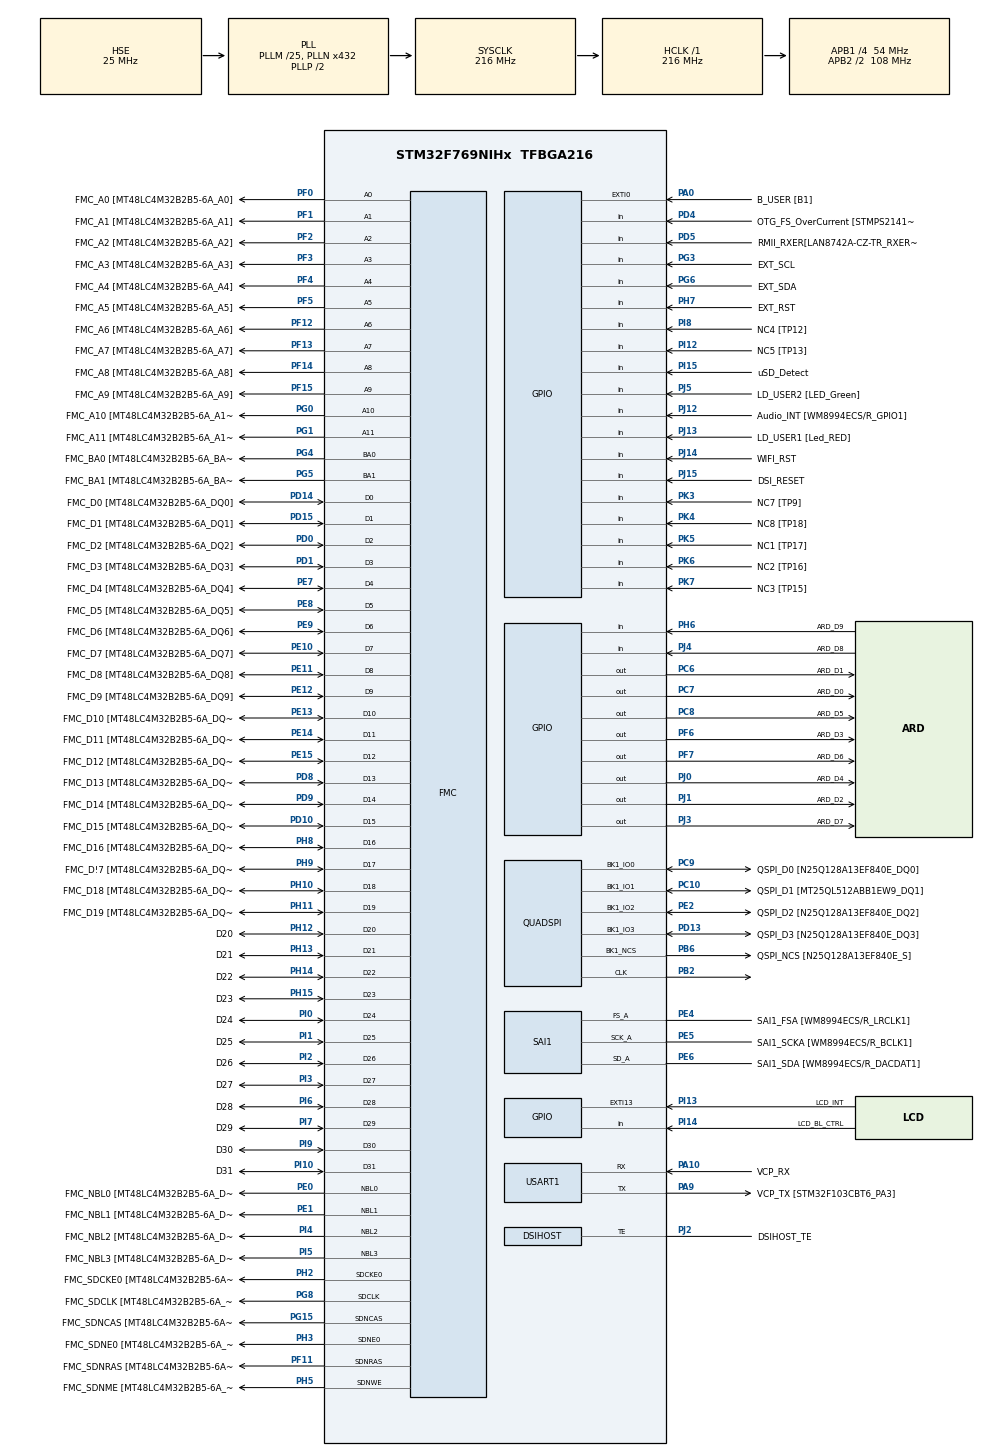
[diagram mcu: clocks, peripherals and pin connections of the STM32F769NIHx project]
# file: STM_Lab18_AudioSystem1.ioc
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CORTEX_M7.CPU_DCache=Enabled
CORTEX_M7.CPU_ICache=Enabled
DSIHOST.CommandSize=400
DSIHOST_CKN.GPIO_Label=DSI_CK_N
DSIHOST_CKN.Mode=DSIHost_Adapted_TE
DSIHOST_CKN.Signal=DSIHOST_CKN
DSIHOST_CKP.GPIO_Label=DSI_CK_P
DSIHOST_CKP.Mode=DSIHost_Adapted_TE
DSIHOST_CKP.Signal=DSIHOST_CKP
DSIHOST_D0N.GPIO_Label=DSI_D0_N
DSIHOST_D0N.Mode=DSIHost_Adapted_TE
DSIHOST_D0N.Signal=DSIHOST_D0N
DSIHOST_D0P.GPIO_Label=DSI_D0_p
DSIHOST_D0P.Mode=DSIHost_Adapted_TE
DSIHOST_D0P.Signal=DSIHOST_D0P
DSIHOST_D1N.GPIO_Label=DSI_D1_N
DSIHOST_D1N.Mode=DSIHost_Adapted_TE
DSIHOST_D1N.Signal=DSIHOST_D1N
DSIHOST_D1P.GPIO_Label=DSI_D1_P
DSIHOST_D1P.Mode=DSIHost_Adapted_TE
DSIHOST_D1P.Signal=DSIHOST_D1P
FMC.CASLatency1=FMC_SDRAM_CAS_LATENCY_3
FREERTOS.Queues01=audioQueue,16,uint8_t,0,Dynamic,NULL,NULL
FREERTOS.Tasks01=audioTask,2,128,StartAudioTask,Default,NULL,Dynamic,NULL,NULL;auxTask,-3,128,auxTaskStart,Default,NULL,Dynamic,NULL,NULL;myFlashAliveTas,-3,128,StartFlashAliveTask,Default,NULL,Dynamic,NULL,NULL
FREERTOS.configUSE_NEWLIB_REENTRANT=1
LTDC.ActiveW=800
LTDC.HBP=1
LTDC.HFP=1
LTDC.HSync=1
LTDC.VBP=1
LTDC.VFP=1
LTDC.VSync=1
Mcu.Family=STM32F7
Mcu.Name=STM32F769NIHx
Mcu.Package=TFBGA216
NVIC.DMA2D_IRQn=true\:5\:0\:false\:false\:true\:true\:true\:true\:true
NVIC.DSI_IRQn=true\:5\:0\:true\:false\:true\:true\:true\:true\:true
NVIC.LTDC_IRQn=true\:5\:0\:false\:false\:true\:true\:true\:true\:true
NVIC.PriorityGroup=NVIC_PRIORITYGROUP_4
NVIC.RCC_IRQn=true\:5\:0\:false\:false\:true\:true\:true\:false\:true
NVIC.TIM6_DAC_IRQn=true\:15\:0\:false\:false\:true\:false\:false\:true\:true
NVIC.TimeBase=TIM6_DAC_IRQn
NVIC.TimeBaseIP=TIM6
PA0/WKUP.GPIO_Label=B_USER [B1]
PA0/WKUP.Signal=GPXTI0
PA1.GPIO_Label=RMII_REF_CLK [LAN8742A-CZ-TR_REFCLK0]
PA1.Signal=ETH_REF_CLK
PA10.GPIO_Label=VCP_RX 
PA10.Mode=Asynchronous
PA10.Signal=USART1_RX
PA11.GPIO_Label=SPI2_NSS
PA11.Signal=SPI2_NSS
PA12.GPIO_Label=ARD_D13/SCK
PA12.GPIO_Mode=GPIO_MODE_AF_PP
PA12.GPIO_PuPd=GPIO_NOPULL
PA12.GPIO_Speed=GPIO_SPEED_FREQ_LOW
PA12.Signal=SPI2_SCK
PA13.GPIO_Label=SWDIO
PA13.Mode=Serial_Wire
PA13.Signal=SYS_JTMS-SWDIO
PA14.GPIO_Label=SWCLK
PA14.Mode=Serial_Wire
PA14.Signal=SYS_JTCK-SWCLK
PA15.GPIO_Label=CEC
PA15.Signal=CEC
PA2.GPIO_Label=RMII_MDIO [LAN8742A-CZ-TR_MDIO]
PA2.Signal=ETH_MDIO
PA3.GPIO_Label=ULPI_D0 [USB3320C-EZK_D0]
PA3.Signal=USB_OTG_HS_ULPI_D0
PA4.GPIO_Label=ARD_A1
PA4.Signal=ADCx_IN4
PA5.GPIO_Label=ULPI_CLK [USB3320C-EZK_CLKOUT]
PA5.Signal=USB_OTG_HS_ULPI_CK
PA6.GPIO_Label=ARD_A0
PA6.Signal=ADCx_IN6
PA7.GPIO_Label=RMII_CRS_DV [LAN8742A-CZ-TR_CRS_DV]
PA7.Signal=ETH_CRS_DV
PA8.GPIO_Label=CEC_CLK [TP2]
PA8.Signal=RCC_MCO_1
PA9.GPIO_Label=VCP_TX [STM32F103CBT6_PA3]
PA9.GPIO_Mode=GPIO_MODE_AF_PP
PA9.GPIO_PuPd=GPIO_NOPULL
PA9.GPIO_Speed=GPIO_SPEED_FREQ_LOW
PA9.Mode=Asynchronous
PA9.Signal=USART1_TX
PB0.GPIO_Label=ULPI_D1 [USB3320C-EZK_D1]
PB0.Signal=USB_OTG_HS_ULPI_D1
PB1.GPIO_Label=ULPI_D2 [USB3320C-EZK_D2]
PB1.Signal=USB_OTG_HS_ULPI_D2
PB10.GPIO_Label=ULPI_D3 [USB3320C-EZK_D3]
PB10.Signal=USB_OTG_HS_ULPI_D3
PB11.GPIO_Label=ULPI_D4 [USB3320C-EZK_D4]
PB11.Signal=USB_OTG_HS_ULPI_D4
PB12.GPIO_Label=ULPI_D5 [USB3320C-EZK_D5]
PB12.Signal=USB_OTG_HS_ULPI_D5
PB13.GPIO_Label=ULPI_D6 [USB3320C-EZK_D6]
PB13.Signal=USB_OTG_HS_ULPI_D6
PB14.GPIO_Label=ARDUINO MISO/D12
PB14.GPIO_Mode=GPIO_MODE_AF_PP
PB14.GPIO_PuPd=GPIO_NOPULL
PB14.GPIO_Speed=GPIO_SPEED_FREQ_LOW
PB14.Signal=SPI2_MISO
PB15.GPIO_Label=ARDUINO MOSI/PWM/D11
PB15.GPIO_Mode=GPIO_MODE_AF_PP
PB15.GPIO_PuPd=GPIO_NOPULL
PB15.GPIO_Speed=GPIO_SPEED_FREQ_LOW
PB15.Signal=SPI2_MOSI
PB2.Mode=Single Bank 1
PB2.Signal=QUADSPI_CLK
PB3.GPIO_Label=uSD_D2
PB3.Signal=SDMMC2_D2
PB4.GPIO_Label=uSD_D3
PB4.Signal=SDMMC2_D3
PB5.GPIO_Label=ULPI_D7 [USB3320C-EZK_D7]
PB5.Signal=USB_OTG_HS_ULPI_D7
PB6.GPIO_Label=QSPI_NCS [N25Q128A13EF840E_S]
PB6.Mode=Single Bank 1
PB6.Signal=QUADSPI_BK1_NCS
PB7.GPIO_Label=AUDIO_SDA [WM8994ECS/R_SDA]
PB7.Signal=I2C4_SDA
PB8.GPIO_Label=ARDUINO SCL/D15
PB8.GPIO_Mode=GPIO_MODE_AF_OD
PB8.GPIO_PuPd=GPIO_NOPULL
PB8.GPIO_Speed=GPIO_SPEED_FREQ_LOW
PB8.Signal=I2C1_SCL
PB9.GPIO_Label=ARDUINO SDA/D14
PB9.GPIO_Mode=GPIO_MODE_AF_OD
PB9.GPIO_PuPd=GPIO_NOPULL
PB9.GPIO_Speed=GPIO_SPEED_FREQ_LOW
PB9.Signal=I2C1_SDA
PC0.GPIO_Label=ULPI_STP [USB3320C-EZK_STP]
PC0.Signal=USB_OTG_HS_ULPI_STP
PC1.GPIO_Label=RMII_MDC [LAN8742A-CZ-TR_MDC]
PC1.Signal=ETH_MDC
PC10.GPIO_Label=QSPI_D1 [MT25QL512ABB1EW9_DQ1]
PC10.Mode=Single Bank 1
PC10.Signal=QUADSPI_BK1_IO1
PC11.GPIO_Label=DFSDM_DATIN5 [TP100]
PC11.Signal=S_DATAIN5DFSDM1
PC12.GPIO_Label=WIFI_RX
PC12.Signal=UART5_TX
PC14/OSC32_IN.GPIO_Label=RCC_OSC32_IN
PC14/OSC32_IN.Signal=RCC_OSC32_IN
PC15/OSC32_OUT.GPIO_Label=RCC_OSC32_OUT
PC15/OSC32_OUT.Signal=RCC_OSC32_OUT
PC2.GPIO_Label=ARD_A2
PC2.Signal=ADCx_IN12
PC3.GPIO_Label=DFSDM_DATIN1 [TP101]
PC3.Signal=S_DATAIN1DFSDM1
PC4.GPIO_Label=RMII_RXD0 [LAN8742A-CZ-TR_RXD0]
PC4.Signal=ETH_RXD0
PC5.GPIO_Label=RMII_RXD1 [LAN8742A-CZ-TR_RXD1]
PC5.Signal=ETH_RXD1
PC6.GPIO_Label=ARD_D1
PC6.Signal=GPIO_Output
PC7.GPIO_Label=ARD_D0
PC7.Signal=GPIO_Output
PC8.GPIO_Label=ARD_D5
PC8.Signal=GPIO_Output
PC9.GPIO_Label=QSPI_D0 [N25Q128A13EF840E_DQ0]
PC9.Mode=Single Bank 1
PC9.Signal=QUADSPI_BK1_IO0
PD0.GPIO_Label=FMC_D2 [MT48LC4M32B2B5-6A_DQ2]
PD0.Signal=FMC_D2_DA2
PD1.GPIO_Label=FMC_D3 [MT48LC4M32B2B5-6A_DQ3]
PD1.Signal=FMC_D3_DA3
PD10.GPIO_Label=FMC_D15 [MT48LC4M32B2B5-6A_DQ15]
PD10.Signal=FMC_D15_DA15
PD11.GPIO_Label=SPDIF_TX [TP20]
PD11.Signal=SAI2_SD_A
PD12.GPIO_Label=AUDIO_SCL [WM8994ECS/R_SCLK]
PD12.Signal=I2C4_SCL
PD13.GPIO_Label=QSPI_D3 [N25Q128A13EF840E_DQ3]
PD13.Mode=Single Bank 1
PD13.Signal=QUADSPI_BK1_IO3
PD14.GPIO_Label=FMC_D0 [MT48LC4M32B2B5-6A_DQ0]
PD14.Signal=FMC_D0_DA0
PD15.GPIO_Label=FMC_D1 [MT48LC4M32B2B5-6A_DQ1]
PD15.Signal=FMC_D1_DA1
PD2.GPIO_Label=WIFI_TX
PD2.Signal=UART5_RX
PD3.GPIO_Label=DFSDM_CKOUT [TP102]
PD3.Signal=S_CKOUTDFSDM1
PD4.GPIO_Label=OTG_FS_OverCurrent [STMPS2141STR_Fault]
PD4.Signal=GPIO_Input
PD5.GPIO_Label=RMII_RXER[LAN8742A-CZ-TR_RXERR]
PD5.Signal=GPIO_Input
PD6.GPIO_Label=uSD_CLK
PD6.Signal=SDMMC2_CK
PD7.GPIO_Label=uSD_CMD
PD7.Signal=SDMMC2_CMD
PD8.GPIO_Label=FMC_D13 [MT48LC4M32B2B5-6A_DQ13]
PD8.Signal=FMC_D13_DA13
PD9.GPIO_Label=FMC_D14 [MT48LC4M32B2B5-6A_DQ14]
PD9.Signal=FMC_D14_DA14
PE0.GPIO_Label=FMC_NBL0 [MT48LC4M32B2B5-6A_DQM0]
PE0.Signal=FMC_NBL0
PE1.GPIO_Label=FMC_NBL1 [MT48LC4M32B2B5-6A_DQM1]
PE1.Signal=FMC_NBL1
PE10.GPIO_Label=FMC_D7 [MT48LC4M32B2B5-6A_DQ7]
PE10.Signal=FMC_D7_DA7
PE11.GPIO_Label=FMC_D8 [MT48LC4M32B2B5-6A_DQ8]
PE11.Signal=FMC_D8_DA8
PE12.GPIO_Label=FMC_D9 [MT48LC4M32B2B5-6A_DQ9]
PE12.Signal=FMC_D9_DA9
PE13.GPIO_Label=FMC_D10 [MT48LC4M32B2B5-6A_DQ10]
PE13.Signal=FMC_D10_DA10
PE14.GPIO_Label=FMC_D11 [MT48LC4M32B2B5-6A_DQ11]
PE14.Signal=FMC_D11_DA11
PE15.GPIO_Label=FMC_D12 [MT48LC4M32B2B5-6A_DQ12]
PE15.Signal=FMC_D12_DA12
PE2.GPIO_Label=QSPI_D2 [N25Q128A13EF840E_DQ2]
PE2.Mode=Single Bank 1
PE2.Signal=QUADSPI_BK1_IO2
PE3.GPIO_Label=SAI1_SDB [WM8994ECS/R_ADCDAT1]
PE3.Signal=SAI1_SD_B
PE4.GPIO_Label=SAI1_FSA [WM8994ECS/R_LRCLK1]
PE4.Mode=SAI_A_Master
PE4.Signal=SAI1_FS_A
PE5.GPIO_Label=SAI1_SCKA [WM8994ECS/R_BCLK1]
PE5.Mode=SAI_A_Master
PE5.Signal=SAI1_SCK_A
PE6.GPIO_Label=SAI1_SDA [WM8994ECS/R_DACDAT1]
PE6.Mode=SAI_A_Master
PE6.Signal=SAI1_SD_A
PE7.GPIO_Label=FMC_D4 [MT48LC4M32B2B5-6A_DQ4]
PE7.Signal=FMC_D4_DA4
PE8.GPIO_Label=FMC_D5 [MT48LC4M32B2B5-6A_DQ5]
PE8.Signal=FMC_D5_DA5
PE9.GPIO_Label=FMC_D6 [MT48LC4M32B2B5-6A_DQ6]
PE9.Signal=FMC_D6_DA6
PF0.GPIO_Label=FMC_A0 [MT48LC4M32B2B5-6A_A0]
PF0.Signal=FMC_A0
PF1.GPIO_Label=FMC_A1 [MT48LC4M32B2B5-6A_A1]
PF1.Signal=FMC_A1
PF10.GPIO_Label=ARDUINO A1
PF10.GPIO_Mode=GPIO_MODE_ANALOG
PF10.GPIO_PuPd=GPIO_NOPULL
PF10.Signal=ADC3_IN8
PF11.GPIO_Label=FMC_SDNRAS [MT48LC4M32B2B5-6A_RAS]
PF11.Signal=FMC_SDNRAS
PF12.GPIO_Label=FMC_A6 [MT48LC4M32B2B5-6A_A6]
PF12.Signal=FMC_A6
PF13.GPIO_Label=FMC_A7 [MT48LC4M32B2B5-6A_A7]
PF13.Signal=FMC_A7
PF14.GPIO_Label=FMC_A8 [MT48LC4M32B2B5-6A_A8]
PF14.Signal=FMC_A8
PF15.GPIO_Label=FMC_A9 [MT48LC4M32B2B5-6A_A9]
PF15.Signal=FMC_A9
PF2.GPIO_Label=FMC_A2 [MT48LC4M32B2B5-6A_A2]
PF2.Signal=FMC_A2
PF3.GPIO_Label=FMC_A3 [MT48LC4M32B2B5-6A_A3]
PF3.Signal=FMC_A3
PF4.GPIO_Label=FMC_A4 [MT48LC4M32B2B5-6A_A4]
PF4.Signal=FMC_A4
PF5.GPIO_Label=FMC_A5 [MT48LC4M32B2B5-6A_A5]
PF5.Signal=FMC_A5
PF6.GPIO_Label=ARD_D3
PF6.Signal=GPIO_Output
PF7.GPIO_Label=ARD_D6
PF7.Signal=GPIO_Output
PF8.GPIO_Label=ARDUINO A3
PF8.GPIO_Mode=GPIO_MODE_ANALOG
PF8.GPIO_PuPd=GPIO_NOPULL
PF8.Signal=ADC3_IN6
PF9.GPIO_Label=ARDUINO A2
PF9.GPIO_Mode=GPIO_MODE_ANALOG
PF9.GPIO_PuPd=GPIO_NOPULL
PF9.Signal=ADC3_IN7
PG0.GPIO_Label=FMC_A10 [MT48LC4M32B2B5-6A_A10]
PG0.Signal=FMC_A10
PG1.GPIO_Label=FMC_A11 [MT48LC4M32B2B5-6A_A11]
PG1.Signal=FMC_A11
PG10.GPIO_Label=uSD_D1
PG10.Signal=SDMMC2_D1
PG11.GPIO_Label=RMII_TX_EN [LAN8742A-CZ-TR_TXEN]
PG11.Signal=ETH_TX_EN
PG12.GPIO_Label=SPDIF_RX [74LVC1G04SE_4]
PG12.Signal=SPDIFRX_IN1
PG13.GPIO_Label=RMII_TXD0 [LAN8742A-CZ-TR_TXD0]
PG13.Signal=ETH_TXD0
PG14.GPIO_Label=RMII_TXD1 [LAN8742A-CZ-TR_TXD1]
PG14.Signal=ETH_TXD1
PG15.GPIO_Label=FMC_SDNCAS [MT48LC4M32B2B5-6A_CAS]
PG15.Signal=FMC_SDNCAS
PG2.GPIO_Label=FMC_A12
PG2.Signal=FMC_A12
PG3.GPIO_Label=EXT_SCL
PG3.Signal=GPIO_Input
PG4.GPIO_Label=FMC_BA0 [MT48LC4M32B2B5-6A_BA0]
PG4.Signal=FMC_A14_BA0
PG5.GPIO_Label=FMC_BA1 [MT48LC4M32B2B5-6A_BA1]
PG5.Signal=FMC_A15_BA1
PG6.GPIO_Label=EXT_SDA
PG6.Signal=GPIO_Input
PG7.GPIO_Label=SAI1_MCLKA [WM8994ECS/R_MCLK1]
PG7.Signal=SAI1_MCLK_A
PG8.GPIO_Label=FMC_SDCLK [MT48LC4M32B2B5-6A_CLK]
PG8.Signal=FMC_SDCLK
PG9.GPIO_Label=uSD_D0
PG9.Signal=SDMMC2_D0
PH0/OSC_IN.GPIO_Label=OSC_25M [NZ2520SB-25.00M_OUT]
PH0/OSC_IN.Mode=HSE-External-Oscillator
PH0/OSC_IN.Signal=RCC_OSC_IN
PH1/OSC_OUT.Mode=HSE-External-Oscillator
PH1/OSC_OUT.Signal=RCC_OSC_OUT
PH10.GPIO_Label=FMC_D18 [MT48LC4M32B2B5-6A_DQ18]
PH10.Signal=FMC_D18
PH11.GPIO_Label=FMC_D19 [MT48LC4M32B2B5-6A_DQ19]
PH11.Signal=FMC_D19
PH12.GPIO_Label=D20
PH12.Signal=FMC_D20
PH13.GPIO_Label=D21
PH13.Signal=FMC_D21
PH14.GPIO_Label=D22
PH14.Signal=FMC_D22
PH15.GPIO_Label=D23
PH15.Signal=FMC_D23
PH2.GPIO_Label=FMC_SDCKE0 [MT48LC4M32B2B5-6A_CKE]
PH2.Mode=SdramChipSelect1_1
PH2.Signal=FMC_SDCKE0
PH3.GPIO_Label=FMC_SDNE0 [MT48LC4M32B2B5-6A_CS]
PH3.Mode=SdramChipSelect1_1
PH3.Signal=FMC_SDNE0
PH4.GPIO_Label=ULPI_NXT [USB3320C-EZK_NXT]
PH4.Signal=USB_OTG_HS_ULPI_NXT
PH5.GPIO_Label=FMC_SDNME [MT48LC4M32B2B5-6A_WE]
PH5.Signal=FMC_SDNWE
PH6.GPIO_Label=ARD_D9
PH6.Signal=GPIO_Input
PH7.GPIO_Label=EXT_RST
PH7.Signal=GPIO_Input
PH8.GPIO_Label=FMC_D16 [MT48LC4M32B2B5-6A_DQ16]
PH8.Signal=FMC_D16
PH9.GPIO_Label=FMC_D\!7 [MT48LC4M32B2B5-6A_DQ17]
PH9.Signal=FMC_D17
PI0.GPIO_Label=D24
PI0.Signal=FMC_D24
PI1.GPIO_Label=D25
PI1.Signal=FMC_D25
PI10.GPIO_Label=D31
PI10.Signal=FMC_D31
PI11.GPIO_Label=ULPI_DIR [USB3320C-EZK_DIR]
PI11.Signal=USB_OTG_HS_ULPI_DIR
PI12.GPIO_Label=NC5 [TP13]
PI12.Signal=GPIO_Input
PI13.GPIO_Label=LCD_INT
PI13.GPIO_ModeDefaultEXTI=GPIO_MODE_EVT_RISING
PI13.Signal=GPXTI13
PI14.GPIO_Label=LCD_BL_CTRL
PI14.Signal=GPIO_Input
PI15.GPIO_Label=uSD_Detect
PI15.Signal=GPIO_Input
PI2.GPIO_Label=D26
PI2.Signal=FMC_D26
PI3.GPIO_Label=D27
PI3.Signal=FMC_D27
PI4.GPIO_Label=FMC_NBL2 [MT48LC4M32B2B5-6A_DQM2]
PI4.Signal=FMC_NBL2
PI5.GPIO_Label=FMC_NBL3 [MT48LC4M32B2B5-6A_DQM3]
PI5.Signal=FMC_NBL3
PI6.GPIO_Label=D28
PI6.Signal=FMC_D28
PI7.GPIO_Label=D29
PI7.Signal=FMC_D29
PI8.GPIO_Label=NC4 [TP12]
PI8.Signal=GPIO_Input
PI9.GPIO_Label=D30
PI9.Signal=FMC_D30
PJ0.GPIO_Label=ARD_D4
PJ0.Signal=GPIO_Output
PJ1.GPIO_Label=ARD_D2
PJ1.Signal=GPIO_Output
PJ12.GPIO_Label=Audio_INT [WM8994ECS/R_GPIO1]
PJ12.Signal=GPIO_Input
PJ13.GPIO_Label=LD_USER1 [Led_RED]
PJ13.Signal=GPIO_Input
PJ14.GPIO_Label=WIFI_RST
PJ14.Signal=GPIO_Input
PJ15.GPIO_Label=DSI_RESET
PJ15.Signal=GPIO_Input
PJ2.GPIO_Label=DSIHOST_TE
PJ2.Mode=DSIHost_Adapted_TE
PJ2.Signal=DSIHOST_TE
PJ3.GPIO_Label=ARD_D7
PJ3.Signal=GPIO_Output
PJ4.GPIO_Label=ARD_D8
PJ4.Signal=GPIO_Input
PJ5.GPIO_Label=LD_USER2 [LED_Green]
PJ5.Signal=GPIO_Input
PK3.GPIO_Label=NC7 [TP9]
PK3.Signal=GPIO_Input
PK4.GPIO_Label=NC8 [TP18]
PK4.Signal=GPIO_Input
PK5.GPIO_Label=NC1 [TP17]
PK5.Signal=GPIO_Input
PK6.GPIO_Label=NC2 [TP16]
PK6.Signal=GPIO_Input
PK7.GPIO_Label=NC3 [TP15]
PK7.Signal=GPIO_Input
ProjectManager.HeapSize=0x200
ProjectManager.StackSize=0x400
ProjectManager.TargetToolchain=STM32CubeIDE
QUADSPI.ClockPrescaler=1
QUADSPI.FifoThreshold=16
RCC.AHBFreq_Value=216000000
RCC.APB1CLKDivider=RCC_HCLK_DIV4
RCC.APB1Freq_Value=54000000
RCC.APB1TimFreq_Value=108000000
RCC.APB2CLKDivider=RCC_HCLK_DIV2
RCC.APB2Freq_Value=108000000
RCC.APB2TimFreq_Value=216000000
RCC.CortexFreq_Value=216000000
RCC.HCLKFreq_Value=216000000
RCC.HSE_VALUE=25000000
RCC.HSI_VALUE=16000000
RCC.LSE_VALUE=32768
RCC.PLLM=25
RCC.PLLN=432
RCC.PLLQ=4
RCC.PLLSAIQ=3
RCC.PLLSourceVirtual=RCC_PLLSOURCE_HSE
RCC.SYSCLKFreq_VALUE=216000000
RCC.SYSCLKSource=RCC_SYSCLKSOURCE_PLLCLK
RCC.USBFreq_Value=108000000
RCC.VCOOutputFreq_Value=432000000
SAI1.ErrorAudioFreq-SAI_A_Master=30.2 %
SAI1.Instance-SAI_A_Master=SAI$Index_Block_A
SAI1.MClockEnable-SAI_A_Master=SAI_MASTERCLOCK_DISABLE
SAI1.RealAudioFreq-SAI_A_Master=250.0 KHz
SAI1.Synchro-SAI_A_Master=SAI_ASYNCHRONOUS
SAI1.VirtualMode-SAI_A_Master=VM_MASTER
SH.ADCx_IN12.0=ADC1_IN12
SH.ADCx_IN4.0=ADC1_IN4
SH.ADCx_IN6.0=ADC1_IN6
SH.FMC_A0.0=FMC_A0,12b-sda1
SH.FMC_A1.0=FMC_A1,12b-sda1
SH.FMC_A10.0=FMC_A10,12b-sda1
SH.FMC_A11.0=FMC_A11,12b-sda1
SH.FMC_A12.0=FMC_A12
SH.FMC_A14_BA0.0=FMC_BA0,FourSdramBanks1
SH.FMC_A15_BA1.0=FMC_BA1,FourSdramBanks1
SH.FMC_A2.0=FMC_A2,12b-sda1
SH.FMC_A3.0=FMC_A3,12b-sda1
SH.FMC_A4.0=FMC_A4,12b-sda1
SH.FMC_A5.0=FMC_A5,12b-sda1
SH.FMC_A6.0=FMC_A6,12b-sda1
SH.FMC_A7.0=FMC_A7,12b-sda1
SH.FMC_A8.0=FMC_A8,12b-sda1
SH.FMC_A9.0=FMC_A9,12b-sda1
SH.FMC_D0_DA0.0=FMC_D0,sd-32b-d1
SH.FMC_D10_DA10.0=FMC_D10,sd-32b-d1
SH.FMC_D11_DA11.0=FMC_D11,sd-32b-d1
SH.FMC_D12_DA12.0=FMC_D12,sd-32b-d1
SH.FMC_D13_DA13.0=FMC_D13,sd-32b-d1
SH.FMC_D14_DA14.0=FMC_D14,sd-32b-d1
SH.FMC_D15_DA15.0=FMC_D15,sd-32b-d1
SH.FMC_D16.0=FMC_D16,sd-32b-d1
SH.FMC_D17.0=FMC_D17,sd-32b-d1
SH.FMC_D18.0=FMC_D18,sd-32b-d1
SH.FMC_D19.0=FMC_D19,sd-32b-d1
SH.FMC_D1_DA1.0=FMC_D1,sd-32b-d1
SH.FMC_D20.0=FMC_D20,sd-32b-d1
SH.FMC_D21.0=FMC_D21,sd-32b-d1
SH.FMC_D22.0=FMC_D22,sd-32b-d1
SH.FMC_D23.0=FMC_D23,sd-32b-d1
SH.FMC_D24.0=FMC_D24,sd-32b-d1
SH.FMC_D25.0=FMC_D25,sd-32b-d1
SH.FMC_D26.0=FMC_D26,sd-32b-d1
SH.FMC_D27.0=FMC_D27,sd-32b-d1
SH.FMC_D28.0=FMC_D28,sd-32b-d1
SH.FMC_D29.0=FMC_D29,sd-32b-d1
SH.FMC_D2_DA2.0=FMC_D2,sd-32b-d1
SH.FMC_D30.0=FMC_D30,sd-32b-d1
SH.FMC_D31.0=FMC_D31,sd-32b-d1
SH.FMC_D3_DA3.0=FMC_D3,sd-32b-d1
SH.FMC_D4_DA4.0=FMC_D4,sd-32b-d1
SH.FMC_D5_DA5.0=FMC_D5,sd-32b-d1
SH.FMC_D6_DA6.0=FMC_D6,sd-32b-d1
SH.FMC_D7_DA7.0=FMC_D7,sd-32b-d1
SH.FMC_D8_DA8.0=FMC_D8,sd-32b-d1
SH.FMC_D9_DA9.0=FMC_D9,sd-32b-d1
SH.FMC_NBL0.0=FMC_NBL0,Sd4ByteEnable1
SH.FMC_NBL1.0=FMC_NBL1,Sd4ByteEnable1
SH.FMC_NBL2.0=FMC_NBL2,Sd4ByteEnable1
SH.FMC_NBL3.0=FMC_NBL3,Sd4ByteEnable1
SH.FMC_SDCLK.0=FMC_SDCLK,12b-sda1
SH.FMC_SDNCAS.0=FMC_SDNCAS,12b-sda1
SH.FMC_SDNRAS.0=FMC_SDNRAS,12b-sda1
SH.FMC_SDNWE.0=FMC_SDNWE,12b-sda1
SH.S_CKOUTDFSDM1.0=DFSDM1_CKOUT
SH.S_DATAIN1DFSDM1.0=DFSDM1_DATIN1
SH.S_DATAIN5DFSDM1.0=DFSDM1_DATIN5
USART1.VirtualMode-Asynchronous=VM_ASYNC
USART1.WordLength=WORDLENGTH_8B
VP_DFSDM1_VS_IN0.Mode=Parallel_Input_ch0
VP_DMA2D_VS_DMA2D.Mode=DMA2D_Activate
VP_FREERTOS_VS_CMSIS_V1.Mode=CMSIS_V1
VP_LTDC_DSIMode.Mode=RGB888
VP_SYS_VS_tim6.Mode=TIM6
board=STM32F769I-DISCO

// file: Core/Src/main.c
/* USER CODE BEGIN Header */
/**
  ******************************************************************************
  * @file           : main.c
  * @brief          : Main program body
  ******************************************************************************
  * @attention
  *
  * Copyright (c) 2023 STMicroelectronics.
  * All rights reserved.
  *
  * This software is licensed under terms that can be found in the LICENSE file
  * in the root directory of this software component.
  * If no LICENSE file comes with this software, it is provided AS-IS.
  *
  ******************************************************************************
  */
/* USER CODE END Header */
#include "main.h"
#include "cmsis_os.h"
#include "dfsdm.h"
#include "dma2d.h"
#include "dsihost.h"
#include "ltdc.h"
#include "quadspi.h"
#include "sai.h"
#include "usart.h"
#include "gpio.h"
#include "fmc.h"

/* USER CODE BEGIN Includes */
#include "test_image_splash.h"

#include <string.h>
#include <stdio.h>

/* USER CODE END Includes */

/* USER CODE BEGIN PV */

/* Private variables ---------------------------------------------------------*/
#ifdef __GNUC__
/* With GCC, small printf (option LD Linker->Libraries->Small printf
   set to 'Yes') calls __io_putchar() */
#define PUTCHAR_PROTOTYPE int __io_putchar(int ch)
#else
#define PUTCHAR_PROTOTYPE int fputc(int ch, FILE *f)
#endif /* __GNUC__ */

static __IO int32_t  front_buffer   = 0;
static __IO int32_t  pend_buffer   = -1;

extern SAI_HandleTypeDef haudio_out_sai, haudio_in_sai; //Can find this type def declared elsewhere

/* Buffer containing the PCM samples coming from the line in/analogue mic */
int16_t RecordBuffer[RECORD_BUFFER_SIZE];
/* Buffer used to stream the recorded PCM samples towards the audio codec. */
int16_t PlaybackBuffer[RECORD_BUFFER_SIZE];

/*In theory..
 *
 * We have a DMA transfer of a LR blocks, both in and out..
 * In a 1 sample, 1 sample out block we 'write' the 1 sample into a circular buffer d[n], then
 * 'read' it out from a delayed location d[n-k], incrementing n per sample
 *
 * In a block transfer system, we can do the same so long as the circular buffer is big enough to hold
 * the incoming blocks of samples. So long as we always process an output blocks worth (getting d[n-k] bigger
 * than the block size is fine), then we will be dandy.
 *
 */

volatile uint32_t  audio_rec_buffer_state; //current buffer status, see above

//Pointer to AudioDriverType
static AUDIO_DrvTypeDef  *audio_drv;

//Touch Screen status
TS_StateTypeDef TS_State = {0};
uint32_t ts_status = TS_OK;

/* USER CODE END PV */

void SystemClock_Config(void);
void PeriphCommonClock_Config(void);
void MX_FREERTOS_Init(void);
/* USER CODE BEGIN PFP */

/* Private function prototypes -----------------------------------------------*/
/*

*/
/* USER CODE END PFP */

/* USER CODE BEGIN 0 */

//Statics are only accessible with main.c, the others are truly global
//not ideal. They're interfaced using main.h which is included in other modules
//Some would benefit from being local to either their associated functions
//or objects.
static uint32_t LCD_X_Size = 0;
static uint32_t LCD_Y_Size = 0;
float coeffOne = 0.5; //Default float value
float coeffTwo = 0.5; //Default float value
float coeffOne_inc = 1/480.0f; //inc, based on size of LCD
float coeffTwo_inc = 1/800.0f; //Ditto

/* random number test */
uint32_t random_x = 0;

//int16_t bufferNumber=0; //FlipBuffers

int16_t CurrentLsample, CurrentRsample;

/**
  * @brief  On Error Handler on condition TRUE.
  * @param  condition : Can be TRUE or FALSE
  * @retval None
  */
void OnError_Handler(uint32_t condition)
{
  if(condition)
  {
    BSP_LED_On(LED1);
    while(1) { ; } /* Blocking on error */
  }
}

uint8_t CheckForUserInput(void)
{
	if (BSP_PB_GetState(BUTTON_WAKEUP) == GPIO_PIN_SET) //This will cause hanging..
		return 1;
	else
		return 0;

//	if(BSP_PB_GetState(BUTTON_WAKEUP) == GPIO_PIN_SET)
//  {
//    //while (BSP_PB_GetState(BUTTON_WAKEUP) == GPIO_PIN_SET); //This will cause hanging..
//    return 1 ;
//  }
//  return 0;
}

/* USER CODE END 0 */

int main(void)
{

  /* Enable I-Cache---------------------------------------------------------*/
  SCB_EnableICache();

  /* Enable D-Cache---------------------------------------------------------*/
  SCB_EnableDCache();

  /* MCU Configuration--------------------------------------------------------*/

  /* Reset of all peripherals, Initializes the Flash interface and the Systick. */
  HAL_Init();

  /* Configure the system clock */
  SystemClock_Config();

/* Configure the peripherals common clocks */
  PeriphCommonClock_Config();

  /* USER CODE BEGIN SysInit */

  //PeripheralInit(); //THIS IS  AUTOGEN BUT UART IS NOT INCLUDED!!?

  /* USER CODE END SysInit */

  /* Initialize all configured peripherals */
  MX_GPIO_Init();
  MX_DFSDM1_Init();
  MX_SAI1_Init();
  MX_USART1_UART_Init();
  MX_LTDC_Init();
  MX_DMA2D_Init();
  MX_DSIHOST_DSI_Init();
  MX_FMC_Init();
  MX_QUADSPI_Init();
  /* USER CODE BEGIN 2 */
  BSP_LED_Init(LED_GREEN);
  BSP_LED_On(LED_GREEN);

  //HAL_StatusTypeDef settingReload = HAL_LTDC_Reload(&hltdc, LTDC_RELOAD_VERTICAL_BLANKING);
  //This will set up the reload interrupt and also the
  //This could potentially? be used to flip the display buffer to create animations..possibly

  //ITM_SendChar ('x');

  printf("Connected to STM32F769I-Discovery USART 1\r\n");
  printf("\r\n");

  // Enable access to the qspi flash chip in memory mapped mode

  uint8_t bsp_status = 0;
  bsp_status = BSP_QSPI_Init();
  OnError_Handler(bsp_status != QSPI_OK);
  bsp_status = BSP_QSPI_EnableMemoryMappedMode();
  OnError_Handler(bsp_status != QSPI_OK);
  HAL_NVIC_DisableIRQ(QUADSPI_IRQn);

  // Enable the LCD
  uint8_t  lcd_status = LCD_OK;
  lcd_status = BSP_LCD_Init();
  OnError_Handler(lcd_status != LCD_OK);

  //All these functions send to use draw immediate which is no good for animation
  //Need to use the lower level commands to do this and switch buffer on LCD blanking reload

  //Set Brightness
  BSP_LCD_SetBrightness(100); //0 - 100 Max

  // Get the LCD Width and Height
  LCD_X_Size = BSP_LCD_GetXSize();
  LCD_Y_Size = BSP_LCD_GetYSize();

  // Configure the LCD layers with their framebuffers in SRAM
  BSP_LCD_LayerDefaultInit(0, LCD_FB_START_ADDRESS);
  BSP_LCD_LayerDefaultInit(1, LCD_FB_START_ADDRESS + (800*480*4));
  BSP_LCD_SetColorKeying(1, LCD_COLOR_TRANSPARENT); //This ensures both layers are visible when overlaid?

  // Draw the image on layer 0
  //This sets the 'internal active layer variable that is used by the drawign routines

  BSP_LCD_SelectLayer(0); //Selects 0 as active  layer index ..all draws will go to zero..

  //This bitmap is defined in image_xxx.h and placed during programming in the EEPROM accessed using the QuadSPI
  // Need to ensure its flashed into the QSPI 64M external before running.
  BSP_LCD_DrawBitmap(0, 0, webb_first_f769idisco);

  //CheckForUserInput(); //wait...

  //We need to try to write to the background (not active layer) then switch to that layer..
 // Draw text on layer one and use transparency to make the background image visible

  BSP_LCD_SelectLayer(1); //Makes 1 the active layer

  //BSP_LCD_DrawBitmap(0, 0, webb_first_f769idisco);

  BSP_LCD_Clear(LCD_COLOR_TRANSPARENT); //So we can see the Layer 0 underneath ..important otherwise layer is overlaid with keying.

  BSP_LCD_SetBackColor(LCD_COLOR_TRANSPARENT); //ditto
  BSP_LCD_SetTextColor(LCD_COLOR_WHITE);
  BSP_LCD_SetFont(&Font24);
  BSP_LCD_DisplayStringAt(0,LINE(2) , (uint8_t *)"Running Demo 1.1", CENTER_MODE);
  BSP_LCD_DisplayStringAt(0,LINE(3) , (uint8_t *)"Audio with Basic Tremolo Effect", CENTER_MODE);

  //BSP_LCD_SelectLayer(1); //Makes 1 the active layer for the box drawing..

  //Will need to move to threads...perhaps?
  ts_status = BSP_TS_Init(BSP_LCD_GetXSize(), BSP_LCD_GetYSize());
  //Could do with calibration..

  if(ts_status == TS_OK)
  {
	  /* Display touch screen active debug */
      printf("Touch screen is go!\r\n");
  }
  OnError_Handler(ts_status != TS_OK);

  //Generate random number
  srandom(12345); //seed
  random_x = random();        // returns a random number

  // Setup
  AUDIO_SETUP();

  /* USER CODE END 2 */

  /* Call init function for freertos objects (in freertos.c) */
  MX_FREERTOS_Init();

  /* Start scheduler */
  osKernelStart();

  /* We should never get here as control is now taken by the scheduler */
  /* Infinite loop */
  while (1)
  {

  }
}

void SystemClock_Config(void)
{
  RCC_OscInitTypeDef RCC_OscInitStruct = {0};
  RCC_ClkInitTypeDef RCC_ClkInitStruct = {0};

  /** Configure the main internal regulator output voltage
  */
  __HAL_RCC_PWR_CLK_ENABLE();
  __HAL_PWR_VOLTAGESCALING_CONFIG(PWR_REGULATOR_VOLTAGE_SCALE1);

  /** Initializes the RCC Oscillators according to the specified parameters
  * in the RCC_OscInitTypeDef structure.
  */
  RCC_OscInitStruct.OscillatorType = RCC_OSCILLATORTYPE_HSE;
  RCC_OscInitStruct.HSEState = RCC_HSE_ON;
  RCC_OscInitStruct.PLL.PLLState = RCC_PLL_ON;
  RCC_OscInitStruct.PLL.PLLSource = RCC_PLLSOURCE_HSE;
  RCC_OscInitStruct.PLL.PLLM = 25;
  RCC_OscInitStruct.PLL.PLLN = 432;
  RCC_OscInitStruct.PLL.PLLP = RCC_PLLP_DIV2;
  RCC_OscInitStruct.PLL.PLLQ = 4;
  RCC_OscInitStruct.PLL.PLLR = 2;
  if (HAL_RCC_OscConfig(&RCC_OscInitStruct) != HAL_OK)
  {
    Error_Handler();
  }

  /** Activate the Over-Drive mode
  */
  if (HAL_PWREx_EnableOverDrive() != HAL_OK)
  {
    Error_Handler();
  }

  /** Initializes the CPU, AHB and APB buses clocks
  */
  RCC_ClkInitStruct.ClockType = RCC_CLOCKTYPE_HCLK|RCC_CLOCKTYPE_SYSCLK
                              |RCC_CLOCKTYPE_PCLK1|RCC_CLOCKTYPE_PCLK2;
  RCC_ClkInitStruct.SYSCLKSource = RCC_SYSCLKSOURCE_PLLCLK;
  RCC_ClkInitStruct.AHBCLKDivider = RCC_SYSCLK_DIV1;
  RCC_ClkInitStruct.APB1CLKDivider = RCC_HCLK_DIV4;
  RCC_ClkInitStruct.APB2CLKDivider = RCC_HCLK_DIV2;

  if (HAL_RCC_ClockConfig(&RCC_ClkInitStruct, FLASH_LATENCY_7) != HAL_OK)
  {
    Error_Handler();
  }
}

void PeriphCommonClock_Config(void)
{
  RCC_PeriphCLKInitTypeDef PeriphClkInitStruct = {0};

  /** Initializes the peripherals clock
  */
  PeriphClkInitStruct.PeriphClockSelection = RCC_PERIPHCLK_LTDC|RCC_PERIPHCLK_SAI1;
  PeriphClkInitStruct.PLLSAI.PLLSAIN = 192;
  PeriphClkInitStruct.PLLSAI.PLLSAIR = 2;
  PeriphClkInitStruct.PLLSAI.PLLSAIQ = 3;
  PeriphClkInitStruct.PLLSAI.PLLSAIP = RCC_PLLSAIP_DIV2;
  PeriphClkInitStruct.PLLSAIDivQ = 1;
  PeriphClkInitStruct.PLLSAIDivR = RCC_PLLSAIDIVR_2;
  PeriphClkInitStruct.Sai1ClockSelection = RCC_SAI1CLKSOURCE_PLLSAI;
  if (HAL_RCCEx_PeriphCLKConfig(&PeriphClkInitStruct) != HAL_OK)
  {
    Error_Handler();
  }
}

/* USER CODE BEGIN 4 */

		/**
       * @brief  Retargets the C library printf function to the USART.
       * @param  None
       * @retval None
       */
     PUTCHAR_PROTOTYPE
     {
       /* Place your implementation of fputc here */
       /* e.g. write a character to the USART2 and Loop until the end of transmission */
       HAL_UART_Transmit(&huart1, (uint8_t *)&ch, 1, 0xFFFF);
       //ITM_SendChar (ch);

       return ch;
     }

/*
     int _write(int file, char *ptr, int len)
         {
             int i = 0;
             for (i = 0; i<len; i++)
                 ITM_SendChar((*ptr++));
             return len;
         }
*/

     /* ISR Handlers */

     // USE_HAL_DSI_REGISTER_CALLBACKS ??Where is this  defined..

     void HAL_DSI_EndOfRefreshCallback(DSI_HandleTypeDef *hdsi)
     {
       (void)hdsi;
       if(pend_buffer >= 0)
       {
         /* Disable DSI Wrapper */
         //__HAL_DSI_WRAPPER_DISABLE(&hdsi_discovery);
         /* Update LTDC configuration */
         //LTDC_LAYER(&hltdc_discovery, 0)->CFBAR = ((uint32_t)Buffers[pend_buffer]);
         //__HAL_LTDC_RELOAD_CONFIG(&hltdc_discovery);
         /* Enable DSI Wrapper */
         //__HAL_DSI_WRAPPER_ENABLE(&hdsi_discovery);

         front_buffer = pend_buffer;
         pend_buffer = -1;
       }
     }

     //override of callback
     void HAL_LTDC_ReloadEventCallback(LTDC_HandleTypeDef *hltdc){
    	 //bufferNumber++;
    	 //Plot here?
    	 //BSP_LCD_FillRect(350, 200, 100, 100);
     }

     void DMA2_Stream4_IRQHandler(void)
     {
      HAL_DMA_IRQHandler(haudio_in_sai.hdmarx);
     }

     void DMA2_Stream1_IRQHandler(void)
     {
      HAL_DMA_IRQHandler(haudio_out_sai.hdmatx);
     }

     /*
      * get maximum value of the buffer. VU meter, perhaps?
      */
     void get_max_val(int16_t *buf, uint32_t size, int16_t amp[])
     {
    	 //Look into the structure of this buffer...
         int16_t maxval[4] = { -32768, -32768, -32768, -32768};
         uint32_t idx;
         for (idx = 0 ; idx < size ; idx += 4) {
             if (buf[idx] > maxval[0])
                 maxval[0] = buf[idx];
             if (buf[idx + 1] > maxval[1])
                 maxval[1] = buf[idx + 1];
             if (buf[idx + 2] > maxval[2])
                 maxval[2] = buf[idx + 2];
             if (buf[idx + 3] > maxval[3])
                 maxval[3] = buf[idx + 3];
         }
         memcpy(amp, maxval, sizeof(maxval));
     }

     /**
       * @brief  Audio IN Error callback function.
       * @param  None
       * @retval None
       */
     void BSP_AUDIO_IN_Error_CallBack(void)
     {
         /* This function is called when an Interrupt due to transfer error on or peripheral
            error occurs. */
         /* Display message on the LCD screen */
         //BSP_LCD_SetBackColor(LCD_COLOR_RED);
         //BSP_LCD_DisplayStringAt(0, LINE(14), (uint8_t *)"       DMA  ERROR     ", CENTER_MODE);
    	  printf("BSP_AUDIO_IN_Error_CallBack\r\n");

         /* Stop the program with an infinite loop */

         while (BSP_PB_GetState(BUTTON_WAKEUP) != RESET)
         {
             return;
         }

         /* could also generate a system reset to recover from the error */
         /* .... */
     }

 /**
  * @brief  Starts playing audio stream from a data buffer for a determined size.
  * @param  pBuffer: Pointer to the buffer
  * @param  Size: Number of audio data BYTES.
  * @retval AUDIO_OK if correct communication, else wrong communication
  */
     void SAIx_In_Init(uint32_t AudioFreq)
     {
         /* Initialize SAI1 block A in MASTER TX */
         /* Initialize the haudio_out_sai Instance parameter */
         haudio_out_sai.Instance = AUDIO_OUT_SAIx;

         /* Disable SAI peripheral to allow access to SAI internal registers */
         __HAL_SAI_DISABLE(&haudio_out_sai);

         /* Configure SAI_Block_x */
         haudio_out_sai.Init.MonoStereoMode = SAI_STEREOMODE;
         haudio_out_sai.Init.AudioFrequency = AudioFreq;
         haudio_out_sai.Init.AudioMode      = SAI_MODEMASTER_TX;
         haudio_out_sai.Init.NoDivider      = SAI_MASTERDIVIDER_ENABLE;
         haudio_out_sai.Init.Protocol       = SAI_FREE_PROTOCOL;
         haudio_out_sai.Init.DataSize       = SAI_DATASIZE_16;
         haudio_out_sai.Init.FirstBit       = SAI_FIRSTBIT_MSB;
         haudio_out_sai.Init.ClockStrobing  = SAI_CLOCKSTROBING_FALLINGEDGE;
         haudio_out_sai.Init.Synchro        = SAI_ASYNCHRONOUS;
         haudio_out_sai.Init.OutputDrive    = SAI_OUTPUTDRIVE_ENABLE;
         haudio_out_sai.Init.FIFOThreshold  = SAI_FIFOTHRESHOLD_1QF;
         haudio_out_sai.Init.SynchroExt     = SAI_SYNCEXT_DISABLE;
         haudio_out_sai.Init.CompandingMode = SAI_NOCOMPANDING;
         haudio_out_sai.Init.TriState       = SAI_OUTPUT_NOTRELEASED;
         haudio_out_sai.Init.Mckdiv         = 0;

         /* Configure SAI_Block_x Frame */
         haudio_out_sai.FrameInit.FrameLength       = 64;
         haudio_out_sai.FrameInit.ActiveFrameLength = 32;
         haudio_out_sai.FrameInit.FSDefinition      = SAI_FS_CHANNEL_IDENTIFICATION;
         haudio_out_sai.FrameInit.FSPolarity        = SAI_FS_ACTIVE_LOW;
         haudio_out_sai.FrameInit.FSOffset          = SAI_FS_BEFOREFIRSTBIT;

         /* Configure SAI Block_x Slot */
         haudio_out_sai.SlotInit.FirstBitOffset = 0;
         haudio_out_sai.SlotInit.SlotSize       = SAI_SLOTSIZE_DATASIZE;
         haudio_out_sai.SlotInit.SlotNumber     = 4;
         haudio_out_sai.SlotInit.SlotActive     = CODEC_AUDIOFRAME_SLOT_0123;

         HAL_SAI_Init(&haudio_out_sai);

         /* Initialize SAI1 block B in SLAVE RX synchronous from SAI1 block A */
         /* Initialize the haudio_in_sai Instance parameter */
         haudio_in_sai.Instance = AUDIO_IN_SAIx;

         /* Disable SAI peripheral to allow access to SAI internal registers */
         __HAL_SAI_DISABLE(&haudio_in_sai);

         /* Configure SAI_Block_x */
         haudio_in_sai.Init.MonoStereoMode = SAI_STEREOMODE;
         haudio_in_sai.Init.AudioFrequency = AudioFreq;
         haudio_in_sai.Init.AudioMode      = SAI_MODESLAVE_RX;
         haudio_in_sai.Init.NoDivider      = SAI_MASTERDIVIDER_ENABLE;
         haudio_in_sai.Init.Protocol       = SAI_FREE_PROTOCOL;
         haudio_in_sai.Init.DataSize       = SAI_DATASIZE_16;
         haudio_in_sai.Init.FirstBit       = SAI_FIRSTBIT_MSB;
         haudio_in_sai.Init.ClockStrobing  = SAI_CLOCKSTROBING_FALLINGEDGE;
         haudio_in_sai.Init.Synchro        = SAI_SYNCHRONOUS;
         haudio_in_sai.Init.OutputDrive    = SAI_OUTPUTDRIVE_DISABLE;
         haudio_in_sai.Init.FIFOThreshold  = SAI_FIFOTHRESHOLD_1QF;
         haudio_in_sai.Init.SynchroExt     = SAI_SYNCEXT_DISABLE;
         haudio_in_sai.Init.CompandingMode = SAI_NOCOMPANDING;
         haudio_in_sai.Init.TriState       = SAI_OUTPUT_RELEASED;
         haudio_in_sai.Init.Mckdiv         = 0;

         /* Configure SAI_Block_x Frame */
         haudio_in_sai.FrameInit.FrameLength       = 64;
         haudio_in_sai.FrameInit.ActiveFrameLength = 32;
         haudio_in_sai.FrameInit.FSDefinition      = SAI_FS_CHANNEL_IDENTIFICATION;
         haudio_in_sai.FrameInit.FSPolarity        = SAI_FS_ACTIVE_LOW;
         haudio_in_sai.FrameInit.FSOffset          = SAI_FS_BEFOREFIRSTBIT;

         /* Configure SAI Block_x Slot */
         haudio_in_sai.SlotInit.FirstBitOffset = 0;
         haudio_in_sai.SlotInit.SlotSize       = SAI_SLOTSIZE_DATASIZE;
         haudio_in_sai.SlotInit.SlotNumber     = 4;
         haudio_in_sai.SlotInit.SlotActive     = CODEC_AUDIOFRAME_SLOT_0123;

         HAL_SAI_Init(&haudio_in_sai);

         /* Enable SAI peripheral */
         __HAL_SAI_ENABLE(&haudio_in_sai);

         /* Enable SAI peripheral to generate MCLK */
         __HAL_SAI_ENABLE(&haudio_out_sai);
     }

     /**
       * @brief  Deinitializes the output Audio Codec audio interface (SAI).
       * @retval None
       */
     void SAIx_In_DeInit(void)
     {
         /* Initialize the haudio_in_sai Instance parameter */
         haudio_in_sai.Instance = AUDIO_IN_SAIx;
         haudio_out_sai.Instance = AUDIO_OUT_SAIx;
         /* Disable SAI peripheral */
         __HAL_SAI_DISABLE(&haudio_in_sai);

         HAL_SAI_DeInit(&haudio_in_sai);
         HAL_SAI_DeInit(&haudio_out_sai);
     }

     /**
       * @brief  Initializes SAI Audio IN MSP.
       * @param  hsai: SAI handle
       * @retval None
       */
     void SAI_AUDIO_IN_MspInit(SAI_HandleTypeDef *hsai, void *Params)
     {
         static DMA_HandleTypeDef hdma_sai_rx;
         GPIO_InitTypeDef  gpio_init_structure;

         /* Enable SAI clock */
         AUDIO_IN_SAIx_CLK_ENABLE();

         /* Enable SD GPIO clock */
         AUDIO_IN_SAIx_SD_ENABLE();
         /* CODEC_SAI pin configuration: SD pin */
         gpio_init_structure.Pin = AUDIO_IN_SAIx_SD_PIN;
         gpio_init_structure.Mode = GPIO_MODE_AF_PP;
         gpio_init_structure.Pull = GPIO_NOPULL;
         gpio_init_structure.Speed = GPIO_SPEED_FAST;
         gpio_init_structure.Alternate = AUDIO_IN_SAIx_AF;
         HAL_GPIO_Init(AUDIO_IN_SAIx_SD_GPIO_PORT, &gpio_init_structure);

         /* Enable Audio INT GPIO clock */
         AUDIO_IN_INT_GPIO_ENABLE();
         /* Audio INT pin configuration: input */
         gpio_init_structure.Pin = AUDIO_IN_INT_GPIO_PIN;
         gpio_init_structure.Mode = GPIO_MODE_INPUT;
         gpio_init_structure.Pull = GPIO_NOPULL;
         gpio_init_structure.Speed = GPIO_SPEED_FAST;
         HAL_GPIO_Init(AUDIO_IN_INT_GPIO_PORT, &gpio_init_structure);

         /* Enable the DMA clock */
         AUDIO_IN_SAIx_DMAx_CLK_ENABLE();

         if (hsai->Instance == AUDIO_IN_SAIx)
         {
             /* Configure the hdma_sai_rx handle parameters */
             hdma_sai_rx.Init.Channel             = AUDIO_IN_SAIx_DMAx_CHANNEL;
             hdma_sai_rx.Init.Direction           = DMA_PERIPH_TO_MEMORY;
             hdma_sai_rx.Init.PeriphInc           = DMA_PINC_DISABLE;
             hdma_sai_rx.Init.MemInc              = DMA_MINC_ENABLE;
             hdma_sai_rx.Init.PeriphDataAlignment = AUDIO_IN_SAIx_DMAx_PERIPH_DATA_SIZE;
             hdma_sai_rx.Init.MemDataAlignment    = AUDIO_IN_SAIx_DMAx_MEM_DATA_SIZE;
             hdma_sai_rx.Init.Mode                = DMA_CIRCULAR;
             hdma_sai_rx.Init.Priority            = DMA_PRIORITY_HIGH;
             hdma_sai_rx.Init.FIFOMode            = DMA_FIFOMODE_DISABLE;
             hdma_sai_rx.Init.FIFOThreshold       = DMA_FIFO_THRESHOLD_FULL;
             hdma_sai_rx.Init.MemBurst            = DMA_MBURST_SINGLE;
             hdma_sai_rx.Init.PeriphBurst         = DMA_MBURST_SINGLE;

             hdma_sai_rx.Instance = AUDIO_IN_SAIx_DMAx_STREAM;

             /* Associate the DMA handle */
             __HAL_LINKDMA(hsai, hdmarx, hdma_sai_rx);

             /* Deinitialize the Stream for new transfer */
             HAL_DMA_DeInit(&hdma_sai_rx);

             /* Configure the DMA Stream */
             HAL_DMA_Init(&hdma_sai_rx);
         }

         /* SAI DMA IRQ Channel configuration */
         HAL_NVIC_SetPriority(AUDIO_IN_SAIx_DMAx_IRQ, AUDIO_IN_IRQ_PREPRIO, 0);
         HAL_NVIC_EnableIRQ(AUDIO_IN_SAIx_DMAx_IRQ);

         /* Audio INT IRQ Channel configuration */
         HAL_NVIC_SetPriority(AUDIO_IN_INT_IRQ, AUDIO_IN_IRQ_PREPRIO, 0);
         HAL_NVIC_EnableIRQ(AUDIO_IN_INT_IRQ);
     }

     uint8_t BSP_AUDIO_IN_OUT_Init(uint32_t AudioFreq)
     {
         uint8_t ret = AUDIO_ERROR;

         /* Disable SAI */
         SAIx_In_DeInit();

         /* PLL clock is set depending by the AudioFreq (44.1khz vs 48khz groups) */
         BSP_AUDIO_OUT_ClockConfig(&haudio_in_sai, AudioFreq, NULL);
         haudio_out_sai.Instance = AUDIO_OUT_SAIx;
         haudio_in_sai.Instance = AUDIO_IN_SAIx;
         if (HAL_SAI_GetState(&haudio_in_sai) == HAL_SAI_STATE_RESET)
         {
             BSP_AUDIO_OUT_MspInit(&haudio_out_sai, NULL);
             SAI_AUDIO_IN_MspInit(&haudio_in_sai, NULL);
         }

         SAIx_In_Init(AudioFreq);

         if ((wm8994_drv.ReadID(AUDIO_I2C_ADDRESS)) == WM8994_ID)
         {
             /* Reset the Codec Registers */
             wm8994_drv.Reset(AUDIO_I2C_ADDRESS);
             /* Initialize the audio driver structure */
             audio_drv = &wm8994_drv;
             ret = AUDIO_OK;
         } else {
             ret = AUDIO_ERROR;
         }

         if (ret == AUDIO_OK)
         {
             /* Initialize the codec internal registers */
        	 //INPUT_DEVICE_ANALOG_MIC is the LINE IN input
        	 //100 is MAX volume on the CODEC
        	 audio_drv->Init(AUDIO_I2C_ADDRESS, INPUT_DEVICE_ANALOG_MIC | OUTPUT_DEVICE_HEADPHONE , 65, AudioFreq);
             //audio_drv->Init(AUDIO_I2C_ADDRESS, INPUT_DEVICE_ANALOG_MIC | OUTPUT_DEVICE_HEADPHONE , 100, AudioFreq);
         }

         /* Return AUDIO_OK when all operations are correctly done */
         return ret;
     }

      uint8_t _BSP_AUDIO_OUT_Play(uint16_t* pBuffer, uint32_t Size)
     {
         /* Call the audio Codec Play function */
    	 //This using the correct  size SF
         if (audio_drv->Play(AUDIO_I2C_ADDRESS, (uint16_t *)pBuffer, Size) != 0)
         {
             return AUDIO_ERROR;
         }
         else
         {
             /* Update the Media layer and enable it for play */

        	 //Buffer gets cast to a BYTE pointer, so this only transmits half the buffer
        	 //contents, i.e double buffer.

        	 if (HAL_SAI_Transmit_DMA(&haudio_out_sai, (uint8_t*) pBuffer, Size) !=  HAL_OK)
                 return AUDIO_ERROR;
             return AUDIO_OK;
         }
     }

      void AUDIO_SETUP(void)
           {

               /* Initialize Audio I/O */
               //96K NOT WORKING
               //48K TESTED  OK
               //44K TESTED OK
               //32K TESTED OK
               //22K TESTED OK
               //16K TESTED OK
               //11K NOT WORKING
               //8K  NOT WORKING

    	       //This will all kick off the SAI and configure the CODEC.
    	       //Call back interrupts, handled in main.c will then communicate with the
    	       //audio listene task

               //Change Sampling rate here...
               if (BSP_AUDIO_IN_OUT_Init(BSP_AUDIO_FREQUENCY_48K) == AUDIO_OK)
               {
              	 printf("Audio I/O initialization OK\r\n");
               } else {
              	 printf("Audio I/O initialization failed.\r\n");
              	 Error_Handler();
               }

               // Start Receiving audio into Record Buffer..
               // Audio Buffer is  defined as int16,
               // so this transfer will only begin to receive into half the buffer. Double buff
               //Not  the record buffer size is cast to uint8, so effectively this halfs the
               //bytes that re transferred per block
               HAL_StatusTypeDef res = HAL_SAI_Receive_DMA(&haudio_in_sai, (uint8_t*)RecordBuffer, RECORD_BUFFER_SIZE);
               if (HAL_OK == res)
               {
              	 printf("SAI receive begin OK\r\n");
               } else {
                   printf("SAI receive error: %d\r\n", res);
                   Error_Handler();
               }

               printf("Begin Playback buffer\r\n");

               /* Play the recorded buffer */
               if (_BSP_AUDIO_OUT_Play((uint16_t *) &PlaybackBuffer[0], RECORD_BUFFER_SIZE) == AUDIO_OK)
               {
              	 printf("Audio output OK\r\n");
               } else {
              	 printf("Audio output error\r\n");
              	 Error_Handler();
           	 }
               printf("\r\n");

               audio_rec_buffer_state = BUFFER_OFFSET_NONE; //trap for kickoff

      } // end AUDIO_SETUP function

/* USER CODE END 4 */

void HAL_TIM_PeriodElapsedCallback(TIM_HandleTypeDef *htim)
{
  if (htim->Instance == TIM6) {
    HAL_IncTick();
  }
}

void Error_Handler(void)
{
  /* USER CODE BEGIN Error_Handler_Debug */
  /* User can add his own implementation to report the HAL error return state */
  __disable_irq();
  while (1)
  {
	  BSP_LED_Toggle(LED_RED);
	  HAL_Delay(1000);

  }
  /* USER CODE END Error_Handler_Debug */
}

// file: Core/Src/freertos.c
/* USER CODE BEGIN Header */
/**
  ******************************************************************************
  * File Name          : freertos.c
  * Description        : Code for freertos applications
  ******************************************************************************
  * @attention
  *
  * Copyright (c) 2023 STMicroelectronics.
  * All rights reserved.
  *
  * This software is licensed under terms that can be found in the LICENSE file
  * in the root directory of this software component.
  * If no LICENSE file comes with this software, it is provided AS-IS.
  *
  ******************************************************************************
  */
/* USER CODE END Header */

#include "FreeRTOS.h"
#include "task.h"
#include "main.h"
#include "cmsis_os.h"

/* USER CODE BEGIN Includes */

#include "AudioProcess.hpp" //include the CPP hook

/* USER CODE END Includes */

osThreadId audioTaskHandle;
osThreadId auxTaskHandle;
osThreadId myFlashAliveTasHandle;
osMessageQId audioQueueHandle;

/* USER CODE BEGIN FunctionPrototypes */
void BufferHandling(void); //Called by audio thread to deal with messages and then call copy buffer etc.
void CopyBuffer(int16_t *pbuffer1, int16_t *pbuffer2, uint16_t BlockSize);
/* USER CODE END FunctionPrototypes */

void StartAudioTask(void const * argument);
void auxTaskStart(void const * argument);
void StartFlashAliveTask(void const * argument);

void MX_FREERTOS_Init(void); /* (MISRA C 2004 rule 8.1) */

/* GetIdleTaskMemory prototype (linked to static allocation support) */
void vApplicationGetIdleTaskMemory( StaticTask_t **ppxIdleTaskTCBBuffer, StackType_t **ppxIdleTaskStackBuffer, uint32_t *pulIdleTaskStackSize );

/* USER CODE BEGIN GET_IDLE_TASK_MEMORY */
static StaticTask_t xIdleTaskTCBBuffer;
static StackType_t xIdleStack[configMINIMAL_STACK_SIZE];

void vApplicationGetIdleTaskMemory( StaticTask_t **ppxIdleTaskTCBBuffer, StackType_t **ppxIdleTaskStackBuffer, uint32_t *pulIdleTaskStackSize )
{
  *ppxIdleTaskTCBBuffer = &xIdleTaskTCBBuffer;
  *ppxIdleTaskStackBuffer = &xIdleStack[0];
  *pulIdleTaskStackSize = configMINIMAL_STACK_SIZE;
  /* place for user code */
}
/* USER CODE END GET_IDLE_TASK_MEMORY */

void MX_FREERTOS_Init(void) {

  /* Create the queue(s) */
  /* definition and creation of audioQueue */
  osMessageQDef(audioQueue, 16, uint8_t);
  audioQueueHandle = osMessageCreate(osMessageQ(audioQueue), NULL);

  /* Create the thread(s) */
  /* definition and creation of audioTask */
  osThreadDef(audioTask, StartAudioTask, osPriorityHigh, 0, 128);
  audioTaskHandle = osThreadCreate(osThread(audioTask), NULL);

  /* definition and creation of auxTask */
  osThreadDef(auxTask, auxTaskStart, osPriorityIdle, 0, 128);
  auxTaskHandle = osThreadCreate(osThread(auxTask), NULL);

  /* definition and creation of myFlashAliveTas */
  osThreadDef(myFlashAliveTas, StartFlashAliveTask, osPriorityIdle, 0, 128);
  myFlashAliveTasHandle = osThreadCreate(osThread(myFlashAliveTas), NULL);

}

void StartAudioTask(void const * argument)
{
  /* USER CODE BEGIN StartAudioTask */

  /* Infinite loop */
  for(;;)
  {
	BufferHandling();
    osDelay(1);
  }
  /* USER CODE END StartAudioTask */
}

void auxTaskStart(void const * argument)
{
  /* USER CODE BEGIN auxTaskStart */

  /* Infinite loop */
  for(;;)
  {
	  //HAL_GPIO_TogglePin(GPIOJ, ARD_D4_Pin); //Signify the task is running
      //We can read things and based on wha we read, change Globals
	  ts_status = BSP_TS_GetState(&TS_State);
      if(TS_State.touchDetected){

		  //Due to the capacitive nature, sometimes spurious touches
		  //are detected..so watch this with traps.

		  /* Get X and Y position of the first touch post calibrated */
		  uint16_t x1 = TS_State.touchX[0];
		  uint16_t y1 = TS_State.touchY[0];

		  //Need to check these values in case of spurious values
		  //limit with a mod instruction for example
		  x1 = x1 % 800;
		  y1 = y1 % 480;

		  coeffOne = (float)(480-y1)*coeffOne_inc;
		  coeffTwo = (float)(800-x1)*coeffTwo_inc;

		  //For the Tremolo, interesting effects, 1000 and 2 for below. :)
		  coeffOne = coeffOne * 200; // test mod depth 0..200
		  coeffTwo = coeffTwo * 20;  // test rate 0..20

		  //Check we're still in the audio thread here ..use the LEDS as we're back in main..
		  UpdateObjects(); //This allows it to be called separately now..and also only call if a control has changed

      }

      //BSP_LCD_FillRect(100, 200, 10, 100);

      osDelay(10); //this will slow the scan time of the TS
 }
  /* USER CODE END auxTaskStart */
}

void StartFlashAliveTask(void const * argument)
{
  /* USER CODE BEGIN StartFlashAliveTask */
  /* Infinite loop */

	HAL_GPIO_WritePin(GPIOJ, ARD_D7_Pin, GPIO_PIN_RESET);
	HAL_GPIO_WritePin(GPIOF, ARD_D6_Pin, GPIO_PIN_SET );
	HAL_GPIO_WritePin(GPIOC, ARD_D5_Pin, GPIO_PIN_RESET);
	HAL_GPIO_WritePin(GPIOJ, ARD_D4_Pin, GPIO_PIN_SET);
	HAL_GPIO_WritePin(GPIOF, ARD_D3_Pin,  GPIO_PIN_RESET);
	HAL_GPIO_WritePin(GPIOJ, ARD_D2_Pin, GPIO_PIN_SET);
	HAL_GPIO_WritePin(GPIOC, ARD_D1_Pin,  GPIO_PIN_RESET);
	HAL_GPIO_WritePin(GPIOC, ARD_D0_Pin,  GPIO_PIN_SET);

	for(;;)
	{
		BSP_LED_Toggle(LED_GREEN);//Flash on main board
		//printf("%d\r\n", CurrentLsample);

		//int16_t scaledSample = (abs(CurrentLsample)/10); //gives potentially 100 length
		//printf("%d\r\n", scaledSample);

		//BSP_LCD_FillRect(350, 200, 100, 100);

		//Basic Audio Monitor..

		//flash all the other leds..
		HAL_GPIO_TogglePin(GPIOJ, ARD_D7_Pin);
		HAL_GPIO_TogglePin(GPIOF, ARD_D6_Pin);
		HAL_GPIO_TogglePin(GPIOC, ARD_D5_Pin);
		HAL_GPIO_TogglePin(GPIOJ, ARD_D4_Pin);
		HAL_GPIO_TogglePin(GPIOF, ARD_D3_Pin);
		HAL_GPIO_TogglePin(GPIOJ, ARD_D2_Pin);
		HAL_GPIO_TogglePin(GPIOC, ARD_D1_Pin);
		HAL_GPIO_TogglePin(GPIOC, ARD_D0_Pin);

		osDelay(100);
  }
  /* USER CODE END StartFlashAliveTask */
}

/* USER CODE BEGIN Application */

/*Handle Buffers..
   * Will get called at half and full buffer point so..can copy the contents into
   * L & R buffer then process so long as the copy is quick enough..
   *
   */
 void CopyBuffer(int16_t *pbuffer1, int16_t *pbuffer2, uint16_t BlockSize)
  {

 	 /*
 	  * pbuffer2 is the source
		 	pbuffer1 is the dest
		 	So, always process the source to the destination :)
 	  * The DMA transfers in BYTES and is configured in BYTES so
 	  * it's important when considering indexing and buffer sizes
 	  * An SAI frame is made up of 8  bytes
 	  * Int16  Int16 Int16  Iint16
 	  * This allows transferral of varying sizes of data
 	  * In our case
 	  * L - 1st Int16
 	  * -
 	  * R   3rd Int16
 	  * -
 	  * Our Sample Size is 2 Bytes - Int16
 	  *
 	  *  pbuffer2 is the source
		 pbuffer1 is the dest
 	 	 So..at the point this function is called,  the 'other half' of the buffer is being filled and output
 	 	 therefore we can copy the DMA buffer into a processing buffer (as the DMA is 8  bytes)
 	 	 and then process before copying back
 	 	 So, 2 functions are required, 1 to extract the samples, the  other to return them to the buffer
 	  *
 	  *
 	  *
 	  *
 	  */

     //Lets clear the entire destination playback DMA buffer here..
 	 //We're just clearing  because if we operate only on the left or right
 	 //the  data from  the last block will still be there..
	 //If we're operating on both, this can be removed

 	 for (uint32_t i = 0; i < BlockSize; i++)
 	 {
 		 pbuffer1[i] = 0; //needs  to  be careful as these are still int16_t buffers when we do maths
 	 }

     //Call AudioProcess CPP Access ...

 	 /*Try copy into larger circ buffer here...
 	 * Then AudioProcess would be passed the current read pointer (start of where the input block is in the
 	 * circular buffer, block size, and the
 	 * current output pointer to Playback Buffer, the latter
 	 * being a flip flop between Playback[0] and Playback[size/2]
 	 */

 	 AudioProcess( pbuffer1, pbuffer2, BlockSize);
 	 //This allows audio objects to be C callable defined through AudioProcess.hpp/cpp

} //Copy Buffer function

void BufferHandling(void){

     /* 1st or 2nd half of the record buffer ready for being copied to the Playback buffer */

	osEvent retvalue  = osMessageGet( audioQueueHandle, 1000 );
	uint16_t buffer_state = retvalue.value.v;

    switch(buffer_state){
    	case BUFFER_OFFSET_HALF:{
    		//HAL_GPIO_WritePin(GPIOJ, ARD_D7_Pin, GPIO_PIN_SET); //Indicate rate of half filling buffer
    		//Ready to copy first block of audio samples to output buffer
        	CopyBuffer(&PlaybackBuffer[0],
        	&RecordBuffer[0],
        	RECORD_BUFFER_SIZE / 2);
        	audio_rec_buffer_state = BUFFER_OFFSET_NONE;  //Reset
        	//HAL_GPIO_TogglePin(GPIOC, ARD_D5_Pin);
        	//HAL_GPIO_WritePin(GPIOJ, ARD_D7_Pin, GPIO_PIN_RESET); //Indicate rate of half filling buffer
        	break;
        	}
    	case BUFFER_OFFSET_FULL:{
    		//Ready to copy next block of audio samples to output buffer
    		 CopyBuffer(&PlaybackBuffer[RECORD_BUFFER_SIZE / 2],
        	 &RecordBuffer[RECORD_BUFFER_SIZE / 2],
        	 RECORD_BUFFER_SIZE / 2);
        	 audio_rec_buffer_state = BUFFER_OFFSET_NONE; //Reset
        	 //HAL_GPIO_TogglePin(GPIOC, ARD_D5_Pin);
        	 break;
        	}
        case BUFFER_OFFSET_NONE:{
        	 //Allow subtask like  scan of TS proc
        	 break;
        	 }
        default : {
        	//printf("Error on audio_rec_buffer_state switch\r\n");
        	Error_Handler();
        	break;
        	}
    	} //End of switch
} // end AUDIO_PROCESS function

//These are the important call back functions, declared as weak in the discovery_audio.h/.c
    //So we can override them as needed
    //As they're in main, we will need to make sure they then can see and can send to the FreeRTOS listener
    //thread
    void BSP_AUDIO_OUT_HalfTransfer_CallBack(void)
    {
        //audio_tx_buffer_state = 1;
        //Everything is driven by the receive but we need to have
        //this callback
    }

    /**
      * @brief Manages the DMA Transfer complete interrupt.
      * @param None
      * @retval None
      */
    void BSP_AUDIO_IN_TransferComplete_CallBack(void)
    {
       audio_rec_buffer_state = BUFFER_OFFSET_FULL;
       osMessagePut(audioQueueHandle, audio_rec_buffer_state, 1000); //Send 1
    }

    /**
      * @brief  Manages the DMA Half Transfer complete interrupt.
      * @param  None
      * @retval None
      */
    void BSP_AUDIO_IN_HalfTransfer_CallBack(void)
    {
        audio_rec_buffer_state = BUFFER_OFFSET_HALF;
        osMessagePut(audioQueueHandle, audio_rec_buffer_state, 1000); //Send 1
    }

/* USER CODE END Application */
